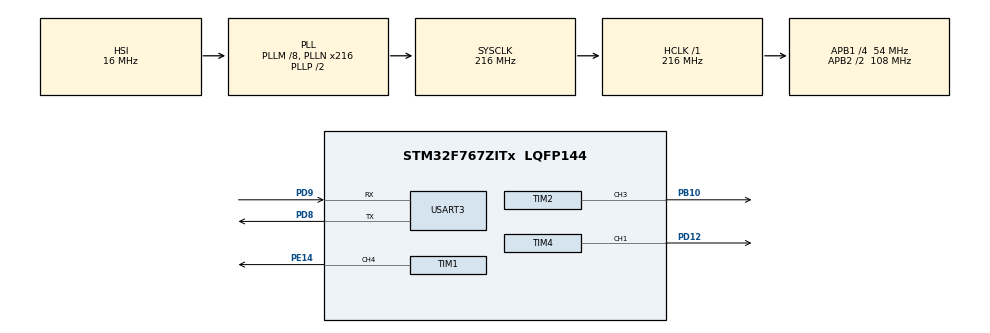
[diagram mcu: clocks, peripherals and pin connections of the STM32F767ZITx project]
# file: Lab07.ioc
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CORTEX_M7.default_mode_Activation=1
Mcu.Family=STM32F7
Mcu.Name=STM32F767ZITx
Mcu.Package=LQFP144
NVIC.PriorityGroup=NVIC_PRIORITYGROUP_4
NVIC.USART3_IRQn=true\:0\:0\:false\:false\:true\:true\:true\:true
PB10.GPIO_Speed=GPIO_SPEED_FREQ_VERY_HIGH
PB10.Signal=S_TIM2_CH3
PB11.Signal=S_TIM2_CH4
PD12.GPIO_Speed=GPIO_SPEED_FREQ_VERY_HIGH
PD12.Signal=S_TIM4_CH1
PD8.Mode=Asynchronous
PD8.Signal=USART3_TX
PD9.Mode=Asynchronous
PD9.Signal=USART3_RX
PE14.GPIO_Speed=GPIO_SPEED_FREQ_VERY_HIGH
PE14.Signal=S_TIM1_CH4
ProjectManager.HeapSize=0x200
ProjectManager.StackSize=0x400
ProjectManager.TargetToolchain=STM32CubeIDE
RCC.AHBFreq_Value=216000000
RCC.APB1CLKDivider=RCC_HCLK_DIV4
RCC.APB1Freq_Value=54000000
RCC.APB1TimFreq_Value=108000000
RCC.APB2CLKDivider=RCC_HCLK_DIV2
RCC.APB2Freq_Value=108000000
RCC.APB2TimFreq_Value=216000000
RCC.CortexFreq_Value=216000000
RCC.HCLKFreq_Value=216000000
RCC.HSE_VALUE=25000000
RCC.HSI_VALUE=16000000
RCC.LSE_VALUE=32768
RCC.PLLM=8
RCC.PLLN=216
RCC.SYSCLKFreq_VALUE=216000000
RCC.SYSCLKSource=RCC_SYSCLKSOURCE_PLLCLK
RCC.USBFreq_Value=216000000
RCC.VCOOutputFreq_Value=432000000
SH.S_TIM1_CH4.0=TIM1_CH4,PWM Generation4 CH4
SH.S_TIM2_CH3.0=TIM2_CH3,PWM Generation3 CH3
SH.S_TIM2_CH4.0=TIM2_CH4
SH.S_TIM4_CH1.0=TIM4_CH1,PWM Generation1 CH1
TIM1.Channel-PWM\ Generation4\ CH4=TIM_CHANNEL_4
TIM1.Period=10000-1
TIM1.Prescaler=108-1
TIM2.Channel-PWM\ Generation3\ CH3=TIM_CHANNEL_3
TIM2.Period=20000-1
TIM2.Prescaler=108-1
TIM2.Pulse-PWM\ Generation3\ CH3=20000/10-1
TIM4.Channel-PWM\ Generation1\ CH1=TIM_CHANNEL_1
TIM4.Period=10000-1
TIM4.Prescaler=108-1
USART3.VirtualMode-Asynchronous=VM_ASYNC
VP_TIM1_VS_ClockSourceINT.Mode=Internal
VP_TIM2_VS_ClockSourceINT.Mode=Internal
VP_TIM4_VS_ClockSourceINT.Mode=Internal
board=custom

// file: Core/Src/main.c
/* USER CODE BEGIN Header */
/**
  ******************************************************************************
  * @file           : main.c
  * @brief          : Main program body
  ******************************************************************************
  * @attention
  *
  * Copyright (c) 2025 STMicroelectronics.
  * All rights reserved.
  *
  * This software is licensed under terms that can be found in the LICENSE file
  * in the root directory of this software component.
  * If no LICENSE file comes with this software, it is provided AS-IS.
  *
  ******************************************************************************
  */
/* USER CODE END Header */
#include "main.h"
#include "tim.h"
#include "usart.h"
#include "gpio.h"

/* USER CODE BEGIN Includes */
#include "stdio.h"
/* USER CODE END Includes */

/* USER CODE BEGIN PV */
// 2.
uint8_t pwm;

//3.
//uint8_t red_pwm;
//uint8_t green_pwm;
//uint8_t blue_pwm;
//
//float red = 0;
//float green = 0;
//float blue = 0;
//
//char rx_cmd;
/* USER CODE END PV */

void SystemClock_Config(void);
static void MPU_Config(void);
/* USER CODE BEGIN PFP */

//void adjust_duty_cycle(float *duty_cycle){
//	if(*duty_cycle >= 1.0){
//		*duty_cycle = 0;
//	}
//	else{
//		*duty_cycle += 0.2;
//	}
//
//}
//
//void display_duty_cycles(float red, float green, float blue){
//    char divider[40] = "______________________________________\r\n";
//	char message[30];
//	int len = sprintf(message, "| R %3d%% | G %3d%% | B %3d%% |\n\r",
//	                  (int)(red * 100),
//	                  (int)(green * 100),
//	                  (int)(blue * 100));
//
//	while(__HAL_UART_GET_FLAG(&huart3,UART_FLAG_TC)==RESET){}
//	HAL_UART_Transmit(&huart3, message, len, 100);
//
//    while(__HAL_UART_GET_FLAG(&huart3,UART_FLAG_TC)==RESET){}
//    HAL_UART_Transmit(&huart3, (uint8_t*)divider, 40, 100);
//}

//void HAL_UART_RxCpltCallback(UART_HandleTypeDef *huart)
//{
//	if (huart->Instance == USART3)
//	{
//		switch (rx_cmd) {
//			case 'r':
//				adjust_duty_cycle(&red);
//				break;
//			case 'g':
//				adjust_duty_cycle(&green);
//				break;
//			case 'b':
//				adjust_duty_cycle(&blue);
//				break;
//			default:
//				break;
//		}
//
//		htim2.Instance -> CCR3 = (10000 - 1) * red;
//		htim1.Instance -> CCR4 = (10000 - 1) * green;
//		htim4.Instance -> CCR1 = (10000 - 1) * blue;
//
//		display_duty_cycles(red, green, blue);
//
//		// Restart receive for next character
////	    const char *msg = "press: ";
////	    HAL_UART_Transmit(&huart3, (uint8_t*)msg, strlen(msg), 100);
//
//		HAL_UART_Receive_IT(&huart3, (uint8_t*)&rx_cmd, 1);
//	}
//}
/* USER CODE END PFP */

int main(void)
{

  /* MPU Configuration--------------------------------------------------------*/
  MPU_Config();

  /* MCU Configuration--------------------------------------------------------*/

  /* Reset of all peripherals, Initializes the Flash interface and the Systick. */
  HAL_Init();

  /* Configure the system clock */
  SystemClock_Config();

  /* Initialize all configured peripherals */
  MX_GPIO_Init();
  MX_TIM2_Init();
  MX_TIM1_Init();
  MX_TIM4_Init();
  MX_USART3_UART_Init();
  /* USER CODE BEGIN 2 */
//  2.
//  float dutyCycle = 0.1;

//  uint32_t arr = __HAL_TIM_GET_AUTORELOAD(&htim2);
//  HAL_Delay(100);

//  HAL_TIM_PWM_Start(&htim2, TIM_CHANNEL_3);
//  HAL_TIM_PWM_Start(&htim1, TIM_CHANNEL_4);
//  HAL_TIM_PWM_Start(&htim4, TIM_CHANNEL_1);
//
//  const char *msg = "press: ";
//  HAL_UART_Transmit(&huart3, (uint8_t*)msg, strlen(msg), HAL_MAX_DELAY);
//
//  HAL_UART_Receive_IT(&huart3, &rx_cmd, 1);

//  	HAL_TIM_PWM_Start(&htim4, TIM_CHANNEL_1);
//	HAL_TIM_PWM_Start(&htim2, TIM_CHANNEL_3);
//	HAL_TIM_PWM_Start(&htim1, TIM_CHANNEL_4);
//
//    HAL_UART_Receive_IT(&huart3, (uint8_t*) &rx_cmd, 1);

  /* USER CODE END 2 */

  /* Infinite loop */
  while (1)
  {

    /* USER CODE BEGIN 3 */

//		red_pwm   = (GPIOB->IDR & GPIO_PIN_10) >> 10;
//		green_pwm = (GPIOE->IDR & GPIO_PIN_14) >> 14;
//		blue_pwm  = (GPIOD->IDR & GPIO_PIN_12) >> 12;
//
//		HAL_Delay(100);
//	  2.
//	  htim2.Instance -> CCR3 = (20000-1)* dutyCycle;
	  htim2.Instance->CCMR2 |= TIM_CCMR2_OC3M_1;
	  HAL_TIM_PWM_Start(&htim2, TIM_CHANNEL_3);
	  HAL_Delay(1000);
	  HAL_TIM_PWM_Stop(&htim2, TIM_CHANNEL_3);

	  htim2.Instance->CCMR2 |= TIM_CCMR2_OC3M_2;
	  HAL_TIM_PWM_Start(&htim2, TIM_CHANNEL_3);
	  HAL_Delay(1000);
	  HAL_TIM_PWM_Stop(&htim2, TIM_CHANNEL_3);
//	  pwm = (GPIOB->IDR & GPIO_PIN_10) >> 10;

//	  3.
//	  char cmd;
//
//	  const char *msg = "press: ";
//	  HAL_UART_Transmit(&huart3, (uint8_t*)msg, strlen(msg), 100);
//
//	  while(__HAL_UART_GET_FLAG(&huart3,UART_FLAG_RXNE)== RESET){}
//	  HAL_UART_Receive(&huart3, (uint8_t*) &cmd, 1, 100);
//
//	  HAL_UART_Transmit(&huart3, (uint8_t*)&cmd, 1, 100);
//	  HAL_UART_Transmit(&huart3, (uint8_t*)"\r\n", 2, 100);
//
//
//	  switch(cmd){
//	  	  case 'r':
//	  		adjust_duty_cycle(&red);
//
//	  		break;
//	  	  case 'g':
//	  		adjust_duty_cycle(&green);
//
//	  		break;
//	  	  case 'b':
//	  		adjust_duty_cycle(&blue);
//			break;
//	  	  default:
//	  		  continue;
//	  }
//
//	  htim2.Instance -> CCR3 = (10000 - 1) * red;
//	  htim1.Instance -> CCR4 = (10000 - 1) * green;
//	  htim4.Instance -> CCR1 = (10000 - 1) * blue;
//
//	  HAL_TIM_PWM_Start(&htim2, TIM_CHANNEL_3);
//	  HAL_TIM_PWM_Start(&htim1, TIM_CHANNEL_4);
//	  HAL_TIM_PWM_Start(&htim4, TIM_CHANNEL_1);
//
//	  HAL_Delay(100);
//
//	  HAL_TIM_PWM_Stop(&htim2, TIM_CHANNEL_3);
//	  HAL_TIM_PWM_Stop(&htim1, TIM_CHANNEL_4);
//	  HAL_TIM_PWM_Stop(&htim4, TIM_CHANNEL_1);
//
//	  display_duty_cycles(red, green, blue);
//
//	  red_pwm = (GPIOB->IDR & GPIO_PIN_10) >> 10;
//	  green_pwm = (GPIOE->IDR & GPIO_PIN_14) >> 14;
//	  blue_pwm = (GPIOD->IDR & GPIO_PIN_12) >> 12;
  }
  /* USER CODE END 3 */
}

void SystemClock_Config(void)
{
  RCC_OscInitTypeDef RCC_OscInitStruct = {0};
  RCC_ClkInitTypeDef RCC_ClkInitStruct = {0};

  /** Configure the main internal regulator output voltage
  */
  __HAL_RCC_PWR_CLK_ENABLE();
  __HAL_PWR_VOLTAGESCALING_CONFIG(PWR_REGULATOR_VOLTAGE_SCALE1);

  /** Initializes the RCC Oscillators according to the specified parameters
  * in the RCC_OscInitTypeDef structure.
  */
  RCC_OscInitStruct.OscillatorType = RCC_OSCILLATORTYPE_HSI;
  RCC_OscInitStruct.HSIState = RCC_HSI_ON;
  RCC_OscInitStruct.HSICalibrationValue = RCC_HSICALIBRATION_DEFAULT;
  RCC_OscInitStruct.PLL.PLLState = RCC_PLL_ON;
  RCC_OscInitStruct.PLL.PLLSource = RCC_PLLSOURCE_HSI;
  RCC_OscInitStruct.PLL.PLLM = 8;
  RCC_OscInitStruct.PLL.PLLN = 216;
  RCC_OscInitStruct.PLL.PLLP = RCC_PLLP_DIV2;
  RCC_OscInitStruct.PLL.PLLQ = 2;
  RCC_OscInitStruct.PLL.PLLR = 2;
  if (HAL_RCC_OscConfig(&RCC_OscInitStruct) != HAL_OK)
  {
    Error_Handler();
  }

  /** Activate the Over-Drive mode
  */
  if (HAL_PWREx_EnableOverDrive() != HAL_OK)
  {
    Error_Handler();
  }

  /** Initializes the CPU, AHB and APB buses clocks
  */
  RCC_ClkInitStruct.ClockType = RCC_CLOCKTYPE_HCLK|RCC_CLOCKTYPE_SYSCLK
                              |RCC_CLOCKTYPE_PCLK1|RCC_CLOCKTYPE_PCLK2;
  RCC_ClkInitStruct.SYSCLKSource = RCC_SYSCLKSOURCE_PLLCLK;
  RCC_ClkInitStruct.AHBCLKDivider = RCC_SYSCLK_DIV1;
  RCC_ClkInitStruct.APB1CLKDivider = RCC_HCLK_DIV4;
  RCC_ClkInitStruct.APB2CLKDivider = RCC_HCLK_DIV2;

  if (HAL_RCC_ClockConfig(&RCC_ClkInitStruct, FLASH_LATENCY_7) != HAL_OK)
  {
    Error_Handler();
  }
}

 /* MPU Configuration */

void MPU_Config(void)
{
  MPU_Region_InitTypeDef MPU_InitStruct = {0};

  /* Disables the MPU */
  HAL_MPU_Disable();

  /** Initializes and configures the Region and the memory to be protected
  */
  MPU_InitStruct.Enable = MPU_REGION_ENABLE;
  MPU_InitStruct.Number = MPU_REGION_NUMBER0;
  MPU_InitStruct.BaseAddress = 0x0;
  MPU_InitStruct.Size = MPU_REGION_SIZE_4GB;
  MPU_InitStruct.SubRegionDisable = 0x87;
  MPU_InitStruct.TypeExtField = MPU_TEX_LEVEL0;
  MPU_InitStruct.AccessPermission = MPU_REGION_NO_ACCESS;
  MPU_InitStruct.DisableExec = MPU_INSTRUCTION_ACCESS_DISABLE;
  MPU_InitStruct.IsShareable = MPU_ACCESS_SHAREABLE;
  MPU_InitStruct.IsCacheable = MPU_ACCESS_NOT_CACHEABLE;
  MPU_InitStruct.IsBufferable = MPU_ACCESS_NOT_BUFFERABLE;

  HAL_MPU_ConfigRegion(&MPU_InitStruct);
  /* Enables the MPU */
  HAL_MPU_Enable(MPU_PRIVILEGED_DEFAULT);

}

void Error_Handler(void)
{
  __disable_irq();
  while (1)
  {
  }
}
